# PIC32MZ2064DAB176 register map
Vendor: Microchip
Registers are 32-bit, read-write, reset 0x0 unless marked. A register's access mark holds for its fields unless they carry their own. Addresses are absolute, and some are shared; only a register's first bit layout is shown; [hi:lo] are bit positions; {n}, {i} and the like mark numbered series.

## GLCD
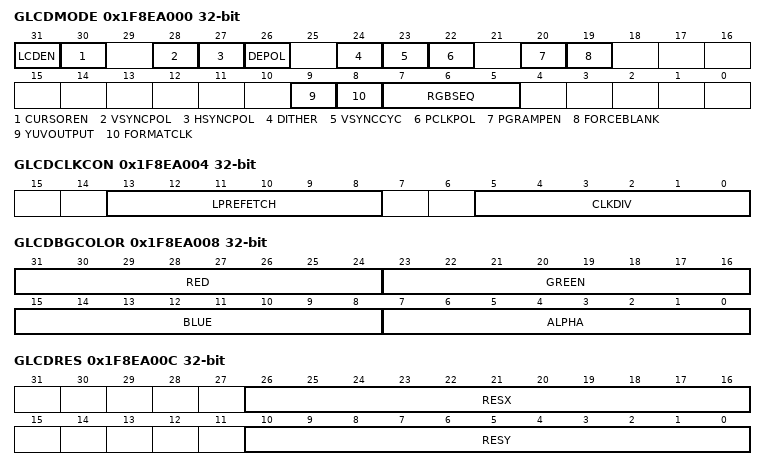
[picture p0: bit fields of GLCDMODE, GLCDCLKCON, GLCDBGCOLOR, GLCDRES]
0x1F8EA000 GLCDMODE
  [31] LCDEN, [30] CURSOREN, [28] VSYNCPOL, [27] HSYNCPOL, [26] DEPOL, [24] DITHER, [23] VSYNCCYC, [22] PCLKPOL, [20] PGRAMPEN, [19] FORCEBLANK, [9] YUVOUTPUT, [8] FORMATCLK, [7:5] RGBSEQ
0x1F8EA004 GLCDCLKCON
  [13:8] LPREFETCH, [5:0] CLKDIV
0x1F8EA008 GLCDBGCOLOR
  [31:24] RED, [23:16] GREEN, [15:8] BLUE, [7:0] ALPHA
0x1F8EA00C GLCDRES
  [26:16] RESX, [10:0] RESY
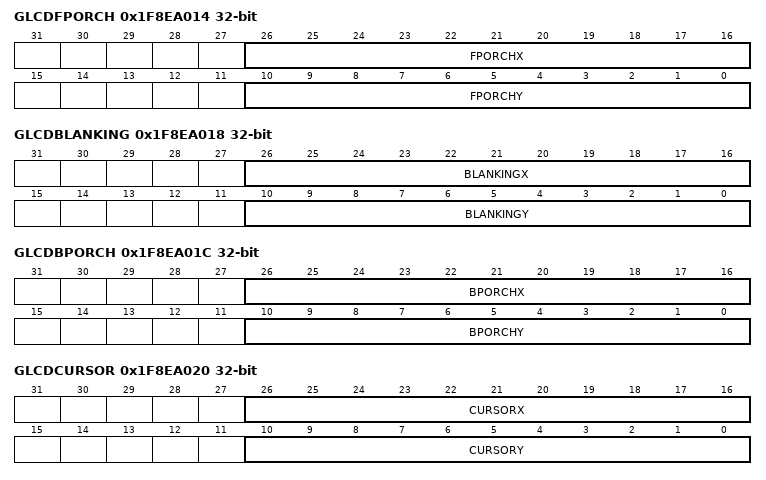
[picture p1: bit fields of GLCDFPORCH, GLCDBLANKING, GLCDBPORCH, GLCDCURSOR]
0x1F8EA014 GLCDFPORCH
  [26:16] FPORCHX, [10:0] FPORCHY
0x1F8EA018 GLCDBLANKING
  [26:16] BLANKINGX, [10:0] BLANKINGY
0x1F8EA01C GLCDBPORCH
  [26:16] BPORCHX, [10:0] BPORCHY
0x1F8EA020 GLCDCURSOR
  [26:16] CURSORX, [10:0] CURSORY
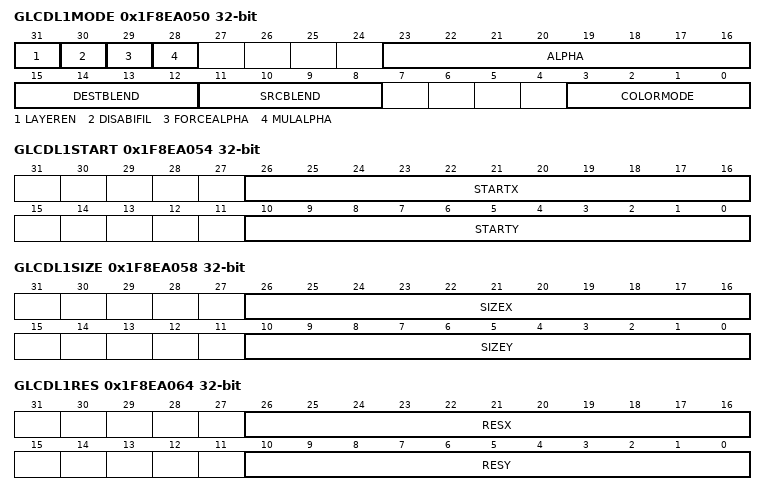
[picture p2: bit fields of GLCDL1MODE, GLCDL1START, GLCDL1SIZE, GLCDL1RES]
0x1F8EA050 GLCDL1MODE
  [31] LAYEREN, [30] DISABIFIL, [29] FORCEALPHA, [28] MULALPHA, [23:16] ALPHA, [15:12] DESTBLEND, [11:8] SRCBLEND, [3:0] COLORMODE
0x1F8EA054 GLCDL1START
  [26:16] STARTX, [10:0] STARTY
0x1F8EA058 GLCDL1SIZE
  [26:16] SIZEX, [10:0] SIZEY
0x1F8EA05C GLCDL1BADDR
  [31:0] BASEADDR
0x1F8EA060 GLCDL1STRIDE
  [15:0] STRIDE
0x1F8EA064 GLCDL1RES
  [26:16] RESX, [10:0] RESY
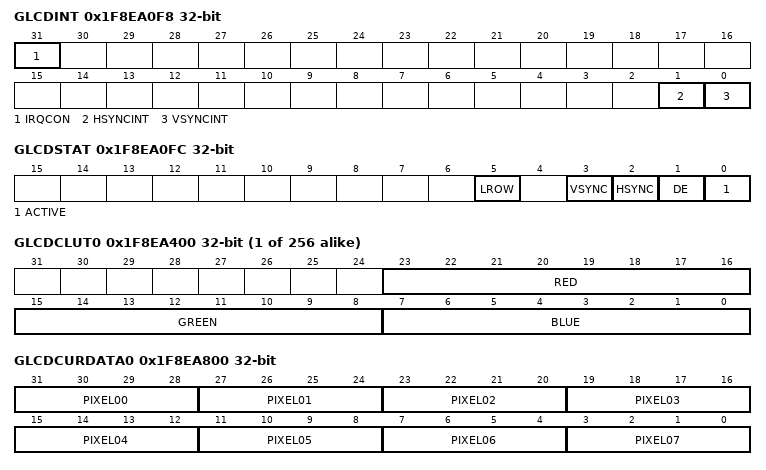
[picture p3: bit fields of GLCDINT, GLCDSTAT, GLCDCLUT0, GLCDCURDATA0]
0x1F8EA0F8 GLCDINT
  [31] IRQCON, [1] HSYNCINT, [0] VSYNCINT
0x1F8EA0FC GLCDSTAT ro
  [5] LROW, [3] VSYNC, [2] HSYNC, [1] DE, [0] ACTIVE
{0x1F8EA400+4i} GLCDCLUT{i} (i=0..255)
  [23:16] RED, [15:8] GREEN, [7:0] BLUE
0x1F8EA800 GLCDCURDATA0
  [31-4n:28-4n] PIXEL{n:02} (n=0..7)
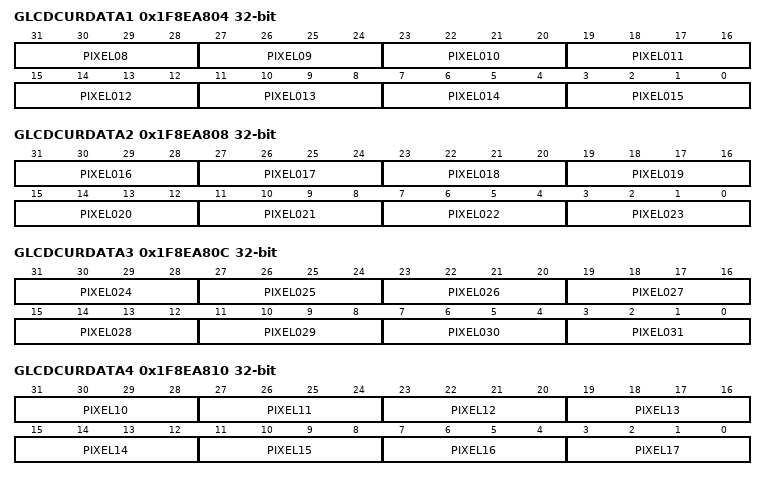
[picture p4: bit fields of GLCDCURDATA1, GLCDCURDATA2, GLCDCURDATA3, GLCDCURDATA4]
0x1F8EA804 GLCDCURDATA1
  [31:28] PIXEL08, [27:24] PIXEL09, [63-4n:60-4n] PIXEL{n:03} (n=10..15)
0x1F8EA808 GLCDCURDATA2
  [95-4n:92-4n] PIXEL{n:03} (n=16..23)
0x1F8EA80C GLCDCURDATA3
  [127-4n:124-4n] PIXEL{n:03} (n=24..31)
0x1F8EA810 GLCDCURDATA4
  [71-4n:68-4n] PIXEL{n} (n=10..17)
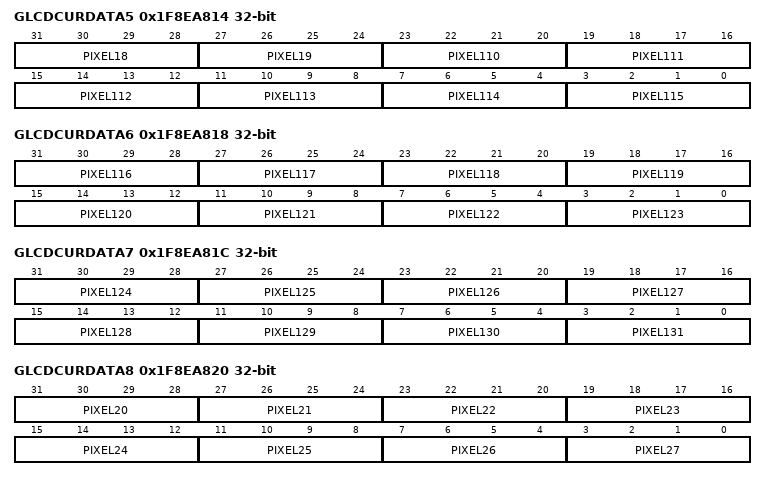
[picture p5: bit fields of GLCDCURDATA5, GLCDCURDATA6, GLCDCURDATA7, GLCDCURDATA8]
0x1F8EA814 GLCDCURDATA5
  [31:28] PIXEL18, [27:24] PIXEL19, [463-4n:460-4n] PIXEL{n} (n=110..115)
0x1F8EA818 GLCDCURDATA6
  [495-4n:492-4n] PIXEL{n} (n=116..123)
0x1F8EA81C GLCDCURDATA7
  [527-4n:524-4n] PIXEL{n} (n=124..131)
0x1F8EA820 GLCDCURDATA8
  [111-4n:108-4n] PIXEL{n} (n=20..27)
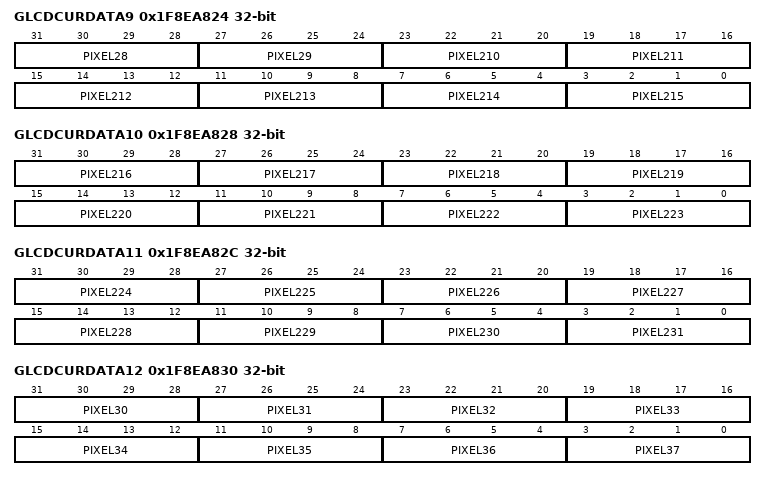
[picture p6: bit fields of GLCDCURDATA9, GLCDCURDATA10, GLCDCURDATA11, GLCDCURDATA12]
0x1F8EA824 GLCDCURDATA9
  [31:28] PIXEL28, [27:24] PIXEL29, [863-4n:860-4n] PIXEL{n} (n=210..215)
0x1F8EA828 GLCDCURDATA10
  [895-4n:892-4n] PIXEL{n} (n=216..223)
0x1F8EA82C GLCDCURDATA11
  [927-4n:924-4n] PIXEL{n} (n=224..231)
0x1F8EA830 GLCDCURDATA12
  [151-4n:148-4n] PIXEL{n} (n=30..37)
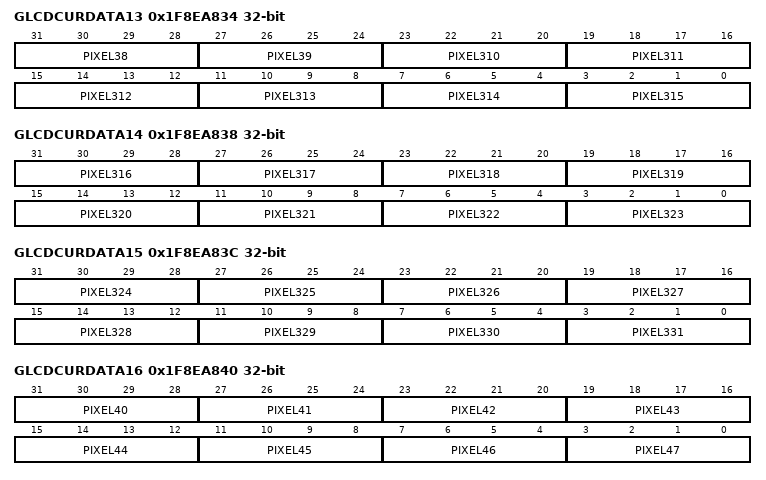
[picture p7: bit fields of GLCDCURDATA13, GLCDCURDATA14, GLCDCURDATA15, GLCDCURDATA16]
0x1F8EA834 GLCDCURDATA13
  [31:28] PIXEL38, [27:24] PIXEL39, [1263-4n:1260-4n] PIXEL{n} (n=310..315)
0x1F8EA838 GLCDCURDATA14
  [1295-4n:1292-4n] PIXEL{n} (n=316..323)
0x1F8EA83C GLCDCURDATA15
  [1327-4n:1324-4n] PIXEL{n} (n=324..331)
0x1F8EA840 GLCDCURDATA16
  [191-4n:188-4n] PIXEL{n} (n=40..47)
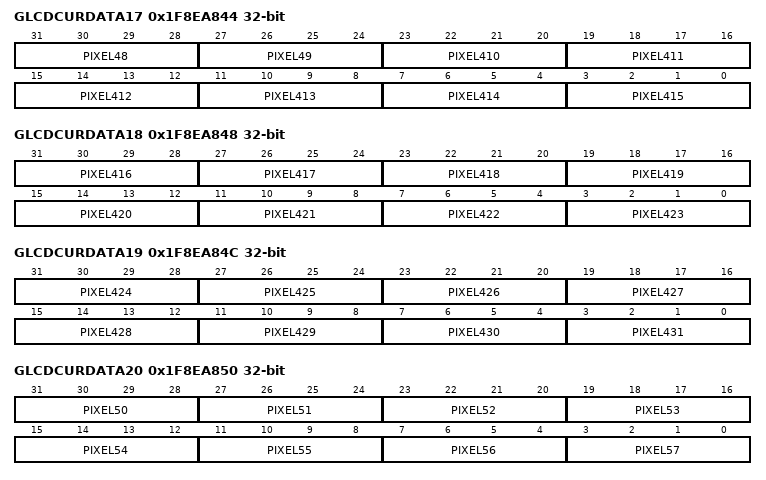
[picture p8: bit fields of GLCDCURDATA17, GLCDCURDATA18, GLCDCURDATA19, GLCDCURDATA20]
0x1F8EA844 GLCDCURDATA17
  [31:28] PIXEL48, [27:24] PIXEL49, [1663-4n:1660-4n] PIXEL{n} (n=410..415)
0x1F8EA848 GLCDCURDATA18
  [1695-4n:1692-4n] PIXEL{n} (n=416..423)
0x1F8EA84C GLCDCURDATA19
  [1727-4n:1724-4n] PIXEL{n} (n=424..431)
0x1F8EA850 GLCDCURDATA20
  [231-4n:228-4n] PIXEL{n} (n=50..57)
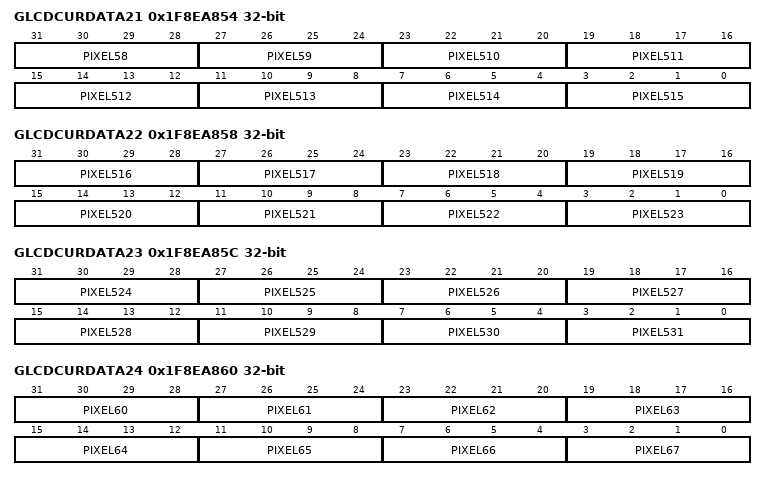
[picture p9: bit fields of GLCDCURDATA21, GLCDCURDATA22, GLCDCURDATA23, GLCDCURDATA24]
0x1F8EA854 GLCDCURDATA21
  [31:28] PIXEL58, [27:24] PIXEL59, [2063-4n:2060-4n] PIXEL{n} (n=510..515)
0x1F8EA858 GLCDCURDATA22
  [2095-4n:2092-4n] PIXEL{n} (n=516..523)
0x1F8EA85C GLCDCURDATA23
  [2127-4n:2124-4n] PIXEL{n} (n=524..531)
0x1F8EA860 GLCDCURDATA24
  [271-4n:268-4n] PIXEL{n} (n=60..67)
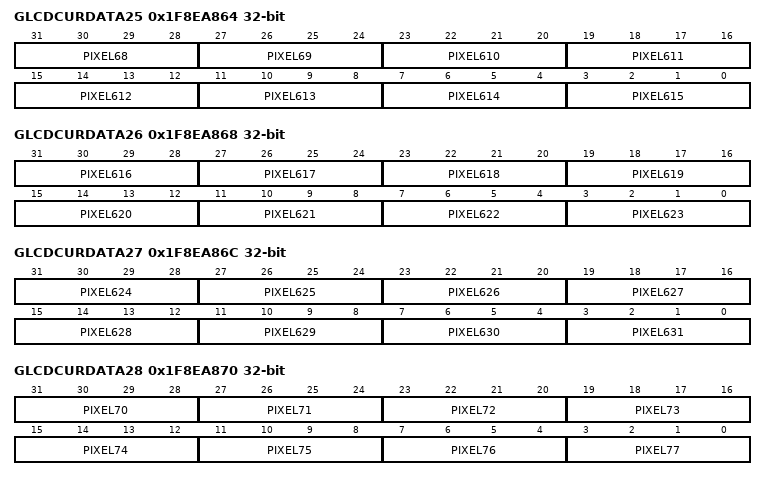
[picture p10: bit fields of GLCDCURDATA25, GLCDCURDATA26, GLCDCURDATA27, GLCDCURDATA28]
0x1F8EA864 GLCDCURDATA25
  [31:28] PIXEL68, [27:24] PIXEL69, [2463-4n:2460-4n] PIXEL{n} (n=610..615)
0x1F8EA868 GLCDCURDATA26
  [2495-4n:2492-4n] PIXEL{n} (n=616..623)
0x1F8EA86C GLCDCURDATA27
  [2527-4n:2524-4n] PIXEL{n} (n=624..631)
0x1F8EA870 GLCDCURDATA28
  [311-4n:308-4n] PIXEL{n} (n=70..77)
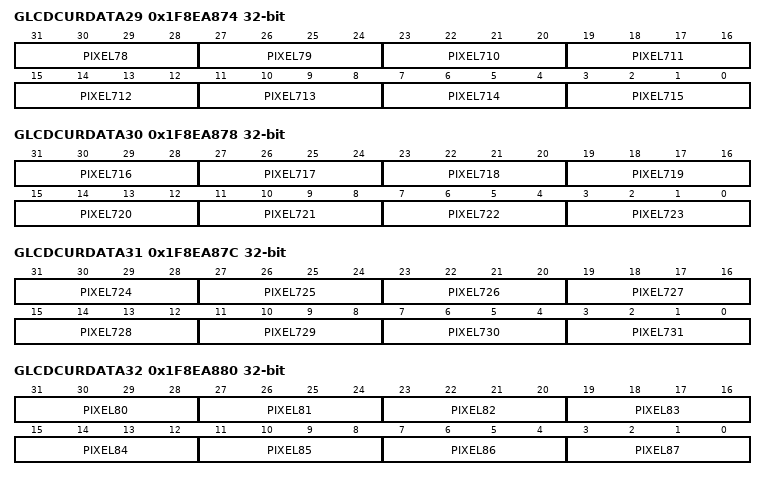
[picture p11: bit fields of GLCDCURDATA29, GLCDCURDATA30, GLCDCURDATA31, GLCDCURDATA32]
0x1F8EA874 GLCDCURDATA29
  [31:28] PIXEL78, [27:24] PIXEL79, [2863-4n:2860-4n] PIXEL{n} (n=710..715)
0x1F8EA878 GLCDCURDATA30
  [2895-4n:2892-4n] PIXEL{n} (n=716..723)
0x1F8EA87C GLCDCURDATA31
  [2927-4n:2924-4n] PIXEL{n} (n=724..731)
0x1F8EA880 GLCDCURDATA32
  [351-4n:348-4n] PIXEL{n} (n=80..87)
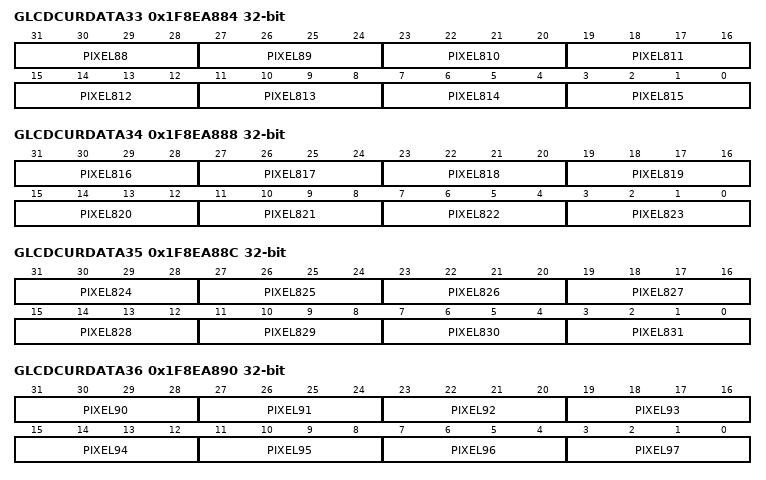
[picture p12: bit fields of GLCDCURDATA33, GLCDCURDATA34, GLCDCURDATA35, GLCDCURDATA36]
0x1F8EA884 GLCDCURDATA33
  [31:28] PIXEL88, [27:24] PIXEL89, [3263-4n:3260-4n] PIXEL{n} (n=810..815)
0x1F8EA888 GLCDCURDATA34
  [3295-4n:3292-4n] PIXEL{n} (n=816..823)
0x1F8EA88C GLCDCURDATA35
  [3327-4n:3324-4n] PIXEL{n} (n=824..831)
0x1F8EA890 GLCDCURDATA36
  [391-4n:388-4n] PIXEL{n} (n=90..97)
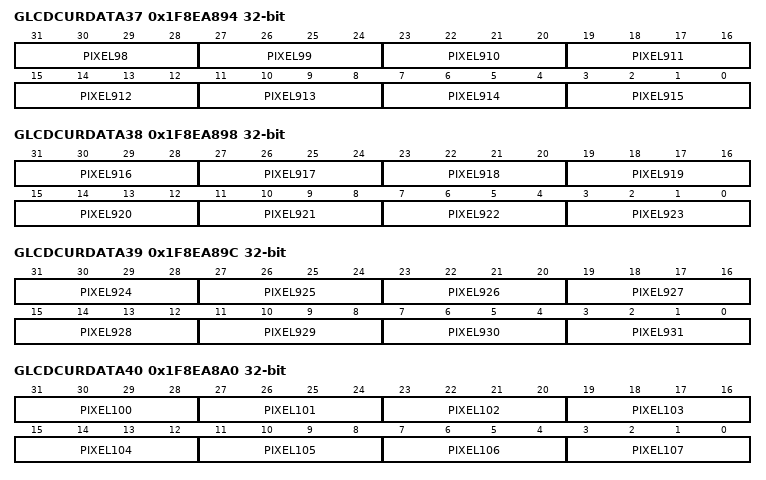
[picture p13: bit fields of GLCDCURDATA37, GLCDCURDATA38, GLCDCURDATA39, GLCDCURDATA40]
0x1F8EA894 GLCDCURDATA37
  [31:28] PIXEL98, [27:24] PIXEL99, [3663-4n:3660-4n] PIXEL{n} (n=910..915)
0x1F8EA898 GLCDCURDATA38
  [3695-4n:3692-4n] PIXEL{n} (n=916..923)
0x1F8EA89C GLCDCURDATA39
  [3727-4n:3724-4n] PIXEL{n} (n=924..931)
0x1F8EA8A0 GLCDCURDATA40
  [431-4n:428-4n] PIXEL{n} (n=100..107)
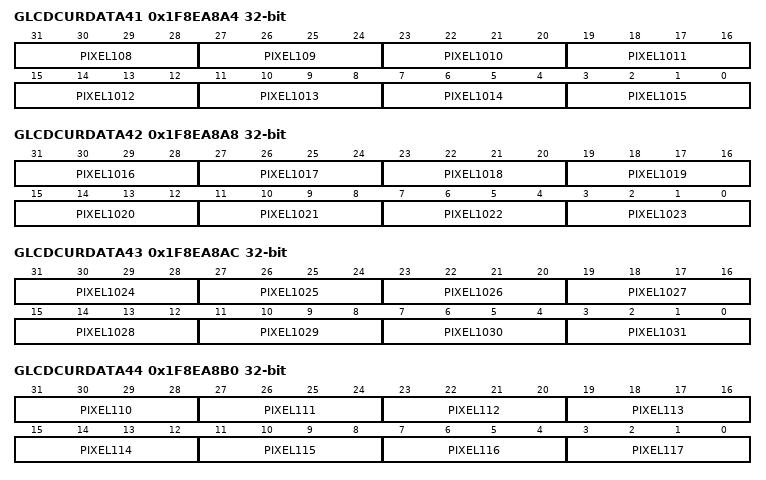
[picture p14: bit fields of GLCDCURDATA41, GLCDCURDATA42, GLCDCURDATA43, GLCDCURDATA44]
0x1F8EA8A4 GLCDCURDATA41
  [31:28] PIXEL108, [27:24] PIXEL109, [4063-4n:4060-4n] PIXEL{n} (n=1010..1015)
0x1F8EA8A8 GLCDCURDATA42
  [4095-4n:4092-4n] PIXEL{n} (n=1016..1023)
0x1F8EA8AC GLCDCURDATA43
  [4127-4n:4124-4n] PIXEL{n} (n=1024..1031)
0x1F8EA8B0 GLCDCURDATA44
  [471-4n:468-4n] PIXEL{n} (n=110..117)
0x1F8EA8B4 GLCDCURDATA45
  [31:28] PIXEL118, [27:24] PIXEL119, [4463-4n:4460-4n] PIXEL{n} (n=1110..1115)
0x1F8EA8B8 GLCDCURDATA46
  [4495-4n:4492-4n] PIXEL{n} (n=1116..1123)
0x1F8EA8BC GLCDCURDATA47
  [4527-4n:4524-4n] PIXEL{n} (n=1124..1131)
0x1F8EA8C0 GLCDCURDATA48
  [511-4n:508-4n] PIXEL{n} (n=120..127)
0x1F8EA8C4 GLCDCURDATA49
  [31:28] PIXEL128, [27:24] PIXEL129, [4863-4n:4860-4n] PIXEL{n} (n=1210..1215)
0x1F8EA8C8 GLCDCURDATA50
  [4895-4n:4892-4n] PIXEL{n} (n=1216..1223)
0x1F8EA8CC GLCDCURDATA51
  [4927-4n:4924-4n] PIXEL{n} (n=1224..1231)
0x1F8EA8D0 GLCDCURDATA52
  [551-4n:548-4n] PIXEL{n} (n=130..137)
0x1F8EA8D4 GLCDCURDATA53
  [31:28] PIXEL138, [27:24] PIXEL139, [5263-4n:5260-4n] PIXEL{n} (n=1310..1315)
0x1F8EA8D8 GLCDCURDATA54
  [5295-4n:5292-4n] PIXEL{n} (n=1316..1323)
0x1F8EA8DC GLCDCURDATA55
  [5327-4n:5324-4n] PIXEL{n} (n=1324..1331)
0x1F8EA8E0 GLCDCURDATA56
  [591-4n:588-4n] PIXEL{n} (n=140..147)
0x1F8EA8E4 GLCDCURDATA57
  [31:28] PIXEL148, [27:24] PIXEL149, [5663-4n:5660-4n] PIXEL{n} (n=1410..1415)
0x1F8EA8E8 GLCDCURDATA58
  [5695-4n:5692-4n] PIXEL{n} (n=1416..1423)
0x1F8EA8EC GLCDCURDATA59
  [5727-4n:5724-4n] PIXEL{n} (n=1424..1431)
0x1F8EA8F0 GLCDCURDATA60
  [631-4n:628-4n] PIXEL{n} (n=150..157)
0x1F8EA8F4 GLCDCURDATA61
  [31:28] PIXEL158, [27:24] PIXEL159, [6063-4n:6060-4n] PIXEL{n} (n=1510..1515)
0x1F8EA8F8 GLCDCURDATA62
  [6095-4n:6092-4n] PIXEL{n} (n=1516..1523)
0x1F8EA8FC GLCDCURDATA63
  [6127-4n:6124-4n] PIXEL{n} (n=1524..1531)
0x1F8EA900 GLCDCURDATA64
  [671-4n:668-4n] PIXEL{n} (n=160..167)
0x1F8EA904 GLCDCURDATA65
  [31:28] PIXEL168, [27:24] PIXEL169, [6463-4n:6460-4n] PIXEL{n} (n=1610..1615)
0x1F8EA908 GLCDCURDATA66
  [6495-4n:6492-4n] PIXEL{n} (n=1616..1623)
0x1F8EA90C GLCDCURDATA67
  [6527-4n:6524-4n] PIXEL{n} (n=1624..1631)
0x1F8EA910 GLCDCURDATA68
  [711-4n:708-4n] PIXEL{n} (n=170..177)
0x1F8EA914 GLCDCURDATA69
  [31:28] PIXEL178, [27:24] PIXEL179, [6863-4n:6860-4n] PIXEL{n} (n=1710..1715)
0x1F8EA918 GLCDCURDATA70
  [6895-4n:6892-4n] PIXEL{n} (n=1716..1723)
0x1F8EA91C GLCDCURDATA71
  [6927-4n:6924-4n] PIXEL{n} (n=1724..1731)
0x1F8EA920 GLCDCURDATA72
  [751-4n:748-4n] PIXEL{n} (n=180..187)
0x1F8EA924 GLCDCURDATA73
  [31:28] PIXEL188, [27:24] PIXEL189, [7263-4n:7260-4n] PIXEL{n} (n=1810..1815)
0x1F8EA928 GLCDCURDATA74
  [7295-4n:7292-4n] PIXEL{n} (n=1816..1823)
0x1F8EA92C GLCDCURDATA75
  [7327-4n:7324-4n] PIXEL{n} (n=1824..1831)
0x1F8EA930 GLCDCURDATA76
  [791-4n:788-4n] PIXEL{n} (n=190..197)
0x1F8EA934 GLCDCURDATA77
  [31:28] PIXEL198, [27:24] PIXEL199, [7663-4n:7660-4n] PIXEL{n} (n=1910..1915)
0x1F8EA938 GLCDCURDATA78
  [7695-4n:7692-4n] PIXEL{n} (n=1916..1923)
0x1F8EA93C GLCDCURDATA79
  [7727-4n:7724-4n] PIXEL{n} (n=1924..1931)
0x1F8EA940 GLCDCURDATA80
  [831-4n:828-4n] PIXEL{n} (n=200..207)
0x1F8EA944 GLCDCURDATA81
  [31:28] PIXEL208, [27:24] PIXEL209, [8063-4n:8060-4n] PIXEL{n} (n=2010..2015)
0x1F8EA948 GLCDCURDATA82
  [8095-4n:8092-4n] PIXEL{n} (n=2016..2023)
0x1F8EA94C GLCDCURDATA83
  [8127-4n:8124-4n] PIXEL{n} (n=2024..2031)
0x1F8EA950 GLCDCURDATA84
  [871-4n:868-4n] PIXEL{n} (n=210..217)
0x1F8EA954 GLCDCURDATA85
  [31:28] PIXEL218, [27:24] PIXEL219, [8463-4n:8460-4n] PIXEL{n} (n=2110..2115)
0x1F8EA958 GLCDCURDATA86
  [8495-4n:8492-4n] PIXEL{n} (n=2116..2123)
0x1F8EA95C GLCDCURDATA87
  [8527-4n:8524-4n] PIXEL{n} (n=2124..2131)
0x1F8EA960 GLCDCURDATA88
  [911-4n:908-4n] PIXEL{n} (n=220..227)
0x1F8EA964 GLCDCURDATA89
  [31:28] PIXEL228, [27:24] PIXEL229, [8863-4n:8860-4n] PIXEL{n} (n=2210..2215)
0x1F8EA968 GLCDCURDATA90
  [8895-4n:8892-4n] PIXEL{n} (n=2216..2223)
0x1F8EA96C GLCDCURDATA91
  [8927-4n:8924-4n] PIXEL{n} (n=2224..2231)
0x1F8EA970 GLCDCURDATA92
  [951-4n:948-4n] PIXEL{n} (n=230..237)
0x1F8EA974 GLCDCURDATA93
  [31:28] PIXEL238, [27:24] PIXEL239, [9263-4n:9260-4n] PIXEL{n} (n=2310..2315)
0x1F8EA978 GLCDCURDATA94
  [9295-4n:9292-4n] PIXEL{n} (n=2316..2323)
0x1F8EA97C GLCDCURDATA95
  [9327-4n:9324-4n] PIXEL{n} (n=2324..2331)
0x1F8EA980 GLCDCURDATA96
  [991-4n:988-4n] PIXEL{n} (n=240..247)
0x1F8EA984 GLCDCURDATA97
  [31:28] PIXEL248, [27:24] PIXEL249, [9663-4n:9660-4n] PIXEL{n} (n=2410..2415)
0x1F8EA988 GLCDCURDATA98
  [9695-4n:9692-4n] PIXEL{n} (n=2416..2423)
0x1F8EA98C GLCDCURDATA99
  [9727-4n:9724-4n] PIXEL{n} (n=2424..2431)
0x1F8EA990 GLCDCURDATA100
  [1031-4n:1028-4n] PIXEL{n} (n=250..257)
0x1F8EA994 GLCDCURDATA101
  [31:28] PIXEL258, [27:24] PIXEL259, [10063-4n:10060-4n] PIXEL{n} (n=2510..2515)
0x1F8EA998 GLCDCURDATA102
  [10095-4n:10092-4n] PIXEL{n} (n=2516..2523)
0x1F8EA99C GLCDCURDATA103
  [10127-4n:10124-4n] PIXEL{n} (n=2524..2531)
0x1F8EA9A0 GLCDCURDATA104
  [1071-4n:1068-4n] PIXEL{n} (n=260..267)
0x1F8EA9A4 GLCDCURDATA105
  [31:28] PIXEL268, [27:24] PIXEL269, [10463-4n:10460-4n] PIXEL{n} (n=2610..2615)
0x1F8EA9A8 GLCDCURDATA106
  [10495-4n:10492-4n] PIXEL{n} (n=2616..2623)
0x1F8EA9AC GLCDCURDATA107
  [10527-4n:10524-4n] PIXEL{n} (n=2624..2631)
0x1F8EA9B0 GLCDCURDATA108
  [1111-4n:1108-4n] PIXEL{n} (n=270..277)
0x1F8EA9B4 GLCDCURDATA109
  [31:28] PIXEL278, [27:24] PIXEL279, [10863-4n:10860-4n] PIXEL{n} (n=2710..2715)
0x1F8EA9B8 GLCDCURDATA110
  [10895-4n:10892-4n] PIXEL{n} (n=2716..2723)
0x1F8EA9BC GLCDCURDATA111
  [10927-4n:10924-4n] PIXEL{n} (n=2724..2731)
0x1F8EA9C0 GLCDCURDATA112
  [1151-4n:1148-4n] PIXEL{n} (n=280..287)
0x1F8EA9C4 GLCDCURDATA113
  [31:28] PIXEL288, [27:24] PIXEL289, [11263-4n:11260-4n] PIXEL{n} (n=2810..2815)
0x1F8EA9C8 GLCDCURDATA114
  [11295-4n:11292-4n] PIXEL{n} (n=2816..2823)
0x1F8EA9CC GLCDCURDATA115
  [11327-4n:11324-4n] PIXEL{n} (n=2824..2831)
0x1F8EA9D0 GLCDCURDATA116
  [1191-4n:1188-4n] PIXEL{n} (n=290..297)
0x1F8EA9D4 GLCDCURDATA117
  [31:28] PIXEL298, [27:24] PIXEL299, [11663-4n:11660-4n] PIXEL{n} (n=2910..2915)
0x1F8EA9D8 GLCDCURDATA118
  [11695-4n:11692-4n] PIXEL{n} (n=2916..2923)
0x1F8EA9DC GLCDCURDATA119
  [11727-4n:11724-4n] PIXEL{n} (n=2924..2931)
0x1F8EA9E0 GLCDCURDATA120
  [1231-4n:1228-4n] PIXEL{n} (n=300..307)
0x1F8EA9E4 GLCDCURDATA121
  [31:28] PIXEL308, [27:24] PIXEL309, [12063-4n:12060-4n] PIXEL{n} (n=3010..3015)
0x1F8EA9E8 GLCDCURDATA122
  [12095-4n:12092-4n] PIXEL{n} (n=3016..3023)
0x1F8EA9EC GLCDCURDATA123
  [12127-4n:12124-4n] PIXEL{n} (n=3024..3031)
0x1F8EA9F0 GLCDCURDATA124
  [1271-4n:1268-4n] PIXEL{n} (n=310..317)
0x1F8EA9F4 GLCDCURDATA125
  [31:28] PIXEL318, [27:24] PIXEL319, [12463-4n:12460-4n] PIXEL{n} (n=3110..3115)
0x1F8EA9F8 GLCDCURDATA126
  [12495-4n:12492-4n] PIXEL{n} (n=3116..3123)
0x1F8EA9FC GLCDCURDATA127
  [12527-4n:12524-4n] PIXEL{n} (n=3124..3131)
0x1F8EAA04 GLCDCURLUT1
  [23:16] RED, [15:8] GREEN, [7:0] BLUE
